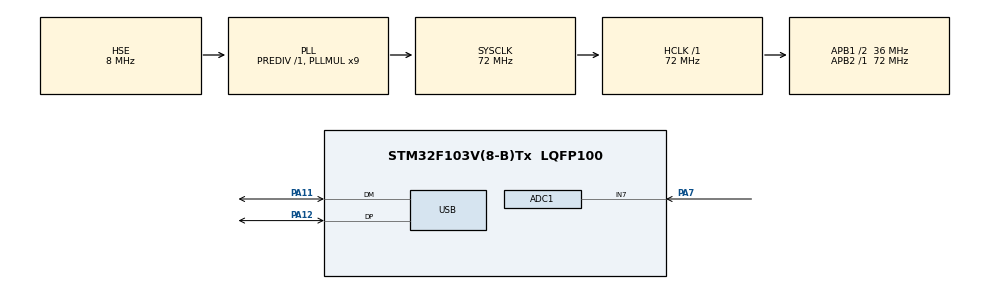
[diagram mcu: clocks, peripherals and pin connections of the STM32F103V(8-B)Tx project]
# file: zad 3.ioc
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ADC1.Channel-0\#ChannelRegularConversion=ADC_CHANNEL_7
ADC1.ContinuousConvMode=ENABLE
ADC1.NbrOfConversion=1
ADC1.NbrOfConversionFlag=1
ADC1.Rank-0\#ChannelRegularConversion=1
ADC1.SamplingTime-0\#ChannelRegularConversion=ADC_SAMPLETIME_1CYCLE_5
ADC1.master=1
Dma.ADC1.0.Direction=DMA_PERIPH_TO_MEMORY
Dma.ADC1.0.Instance=DMA1_Channel1
Dma.ADC1.0.MemDataAlignment=DMA_MDATAALIGN_HALFWORD
Dma.ADC1.0.MemInc=DMA_MINC_DISABLE
Dma.ADC1.0.Mode=DMA_CIRCULAR
Dma.ADC1.0.PeriphDataAlignment=DMA_PDATAALIGN_HALFWORD
Dma.ADC1.0.PeriphInc=DMA_PINC_DISABLE
Dma.ADC1.0.Priority=DMA_PRIORITY_LOW
Dma.Request0=ADC1
Mcu.Family=STM32F1
Mcu.Name=STM32F103V(8-B)Tx
Mcu.Package=LQFP100
NVIC.DMA1_Channel1_IRQn=true\:0\:0\:false\:false\:true\:false\:true\:true
NVIC.PriorityGroup=NVIC_PRIORITYGROUP_4
NVIC.USB_LP_CAN1_RX0_IRQn=true\:0\:0\:false\:false\:true\:false\:true\:true
OSC_IN.Mode=HSE-External-Oscillator
OSC_IN.Signal=RCC_OSC_IN
OSC_OUT.Mode=HSE-External-Oscillator
OSC_OUT.Signal=RCC_OSC_OUT
PA11.Mode=Device
PA11.Signal=USB_DM
PA12.Mode=Device
PA12.Signal=USB_DP
PA13.Mode=JTAG_5_pins
PA13.Signal=SYS_JTMS-SWDIO
PA14.Mode=JTAG_5_pins
PA14.Signal=SYS_JTCK-SWCLK
PA15.Mode=JTAG_5_pins
PA15.Signal=SYS_JTDI
PA7.Signal=ADCx_IN7
PB3.Mode=JTAG_5_pins
PB3.Signal=SYS_JTDO-TRACESWO
PB4.Mode=JTAG_5_pins
PB4.Signal=SYS_NJTRST
PC14-OSC32_IN.Mode=LSE-External-Oscillator
PC14-OSC32_IN.Signal=RCC_OSC32_IN
PC15-OSC32_OUT.Mode=LSE-External-Oscillator
PC15-OSC32_OUT.Signal=RCC_OSC32_OUT
ProjectManager.HeapSize=0x200
ProjectManager.StackSize=0x400
ProjectManager.TargetToolchain=MDK-ARM V5.32
RCC.ADCPresc=RCC_ADCPCLK2_DIV6
RCC.AHBFreq_Value=72000000
RCC.APB1CLKDivider=RCC_HCLK_DIV2
RCC.APB1Freq_Value=36000000
RCC.APB1TimFreq_Value=72000000
RCC.APB2Freq_Value=72000000
RCC.APB2TimFreq_Value=72000000
RCC.HCLKFreq_Value=72000000
RCC.PLLMUL=RCC_PLL_MUL9
RCC.SYSCLKFreq_VALUE=72000000
RCC.SYSCLKSource=RCC_SYSCLKSOURCE_PLLCLK
RCC.USBFreq_Value=48000000
RCC.USBPrescaler=RCC_USBCLKSOURCE_PLL_DIV1_5
SH.ADCx_IN7.0=ADC1_IN7,IN7
USB_DEVICE.CLASS_NAME_FS=CDC
USB_DEVICE.VirtualMode=Cdc
USB_DEVICE.VirtualModeFS=Cdc_FS
VP_USB_DEVICE_VS_USB_DEVICE_CDC_FS.Mode=CDC_FS
board=custom

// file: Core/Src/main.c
/* USER CODE BEGIN Header */
/**
  ******************************************************************************
  * @file           : main.c
  * @brief          : Main program body
  ******************************************************************************
  * @attention
  *
  * Copyright (c) 2023 STMicroelectronics.
  * All rights reserved.
  *
  * This software is licensed under terms that can be found in the LICENSE file
  * in the root directory of this software component.
  * If no LICENSE file comes with this software, it is provided AS-IS.
  *
  ******************************************************************************
  */
/* USER CODE END Header */
#include "main.h"
#include "usb_device.h"

/* USER CODE BEGIN Includes */
#include "USBD_CDC_IF.h"
#include "stdio.h"
#include "lcd4bit.h"
/* USER CODE END Includes */

/* USER CODE BEGIN PD */
#ifdef __GNUC__
#define PUTCHAR_PROTOTYPE int __io_putchar(int ch)
#else
#define PUTCHAR_PROTOTYPE int fputc(int ch, FILE *f)
#endif
PUTCHAR_PROTOTYPE
{
  CDC_Transmit_FS((uint8_t*)&ch,1);
  return ch;
}
/* USER CODE END PD */

ADC_HandleTypeDef hadc1;
DMA_HandleTypeDef hdma_adc1;

/* USER CODE BEGIN PV */
volatile uint32_t ADCVal;
float odleglosc;
char text[10];
Lcd_PortType ports[] = {GPIOC, GPIOC, GPIOC, GPIOC};
Lcd_PinType pins[] = {GPIO_PIN_3, GPIO_PIN_2, GPIO_PIN_1, GPIO_PIN_0};
Lcd_HandleTypeDef lcd;
/* USER CODE END PV */

void SystemClock_Config(void);
static void MX_GPIO_Init(void);
static void MX_DMA_Init(void);
static void MX_ADC1_Init(void);

int main(void)
{

  /* MCU Configuration--------------------------------------------------------*/

  /* Reset of all peripherals, Initializes the Flash interface and the Systick. */
  HAL_Init();

  /* Configure the system clock */
  SystemClock_Config();

  /* Initialize all configured peripherals */
  MX_GPIO_Init();
  MX_DMA_Init();
  MX_ADC1_Init();
  MX_USB_DEVICE_Init();
  /* USER CODE BEGIN 2 */
  HAL_ADC_Start_DMA(&hadc1,&ADCVal,1);
	lcd = Lcd_create(ports, pins, GPIOC, GPIO_PIN_12, GPIOC, GPIO_PIN_10, LCD_4_BIT_MODE);
  /* USER CODE END 2 */

  /* Infinite loop */
  /* USER CODE BEGIN WHILE */
  while (1)
  {
		odleglosc=(3300*ADCVal/4095)/3.2;
		printf("Odleglosc: %f2.3:\n",odleglosc);
		sprintf(text, "%2.3f", odleglosc);
		Lcd_cursor(&lcd,0,0);
		Lcd_string(&lcd,"Odleglosc [cm]:");
		Lcd_cursor(&lcd,1,0);
		Lcd_string(&lcd,text);
		HAL_Delay(1000);
    /* USER CODE END WHILE */

  }
}

void SystemClock_Config(void)
{
  RCC_OscInitTypeDef RCC_OscInitStruct = {0};
  RCC_ClkInitTypeDef RCC_ClkInitStruct = {0};
  RCC_PeriphCLKInitTypeDef PeriphClkInit = {0};

  /** Initializes the RCC Oscillators according to the specified parameters
  * in the RCC_OscInitTypeDef structure.
  */
  RCC_OscInitStruct.OscillatorType = RCC_OSCILLATORTYPE_HSE;
  RCC_OscInitStruct.HSEState = RCC_HSE_ON;
  RCC_OscInitStruct.HSEPredivValue = RCC_HSE_PREDIV_DIV1;
  RCC_OscInitStruct.HSIState = RCC_HSI_ON;
  RCC_OscInitStruct.PLL.PLLState = RCC_PLL_ON;
  RCC_OscInitStruct.PLL.PLLSource = RCC_PLLSOURCE_HSE;
  RCC_OscInitStruct.PLL.PLLMUL = RCC_PLL_MUL9;
  if (HAL_RCC_OscConfig(&RCC_OscInitStruct) != HAL_OK)
  {
    Error_Handler();
  }

  /** Initializes the CPU, AHB and APB buses clocks
  */
  RCC_ClkInitStruct.ClockType = RCC_CLOCKTYPE_HCLK|RCC_CLOCKTYPE_SYSCLK
                              |RCC_CLOCKTYPE_PCLK1|RCC_CLOCKTYPE_PCLK2;
  RCC_ClkInitStruct.SYSCLKSource = RCC_SYSCLKSOURCE_PLLCLK;
  RCC_ClkInitStruct.AHBCLKDivider = RCC_SYSCLK_DIV1;
  RCC_ClkInitStruct.APB1CLKDivider = RCC_HCLK_DIV2;
  RCC_ClkInitStruct.APB2CLKDivider = RCC_HCLK_DIV1;

  if (HAL_RCC_ClockConfig(&RCC_ClkInitStruct, FLASH_LATENCY_2) != HAL_OK)
  {
    Error_Handler();
  }
  PeriphClkInit.PeriphClockSelection = RCC_PERIPHCLK_ADC|RCC_PERIPHCLK_USB;
  PeriphClkInit.AdcClockSelection = RCC_ADCPCLK2_DIV6;
  PeriphClkInit.UsbClockSelection = RCC_USBCLKSOURCE_PLL_DIV1_5;
  if (HAL_RCCEx_PeriphCLKConfig(&PeriphClkInit) != HAL_OK)
  {
    Error_Handler();
  }
}

static void MX_ADC1_Init(void)
{

  ADC_ChannelConfTypeDef sConfig = {0};

  /** Common config
  */
  hadc1.Instance = ADC1;
  hadc1.Init.ScanConvMode = ADC_SCAN_DISABLE;
  hadc1.Init.ContinuousConvMode = ENABLE;
  hadc1.Init.DiscontinuousConvMode = DISABLE;
  hadc1.Init.ExternalTrigConv = ADC_SOFTWARE_START;
  hadc1.Init.DataAlign = ADC_DATAALIGN_RIGHT;
  hadc1.Init.NbrOfConversion = 1;
  if (HAL_ADC_Init(&hadc1) != HAL_OK)
  {
    Error_Handler();
  }

  /** Configure Regular Channel
  */
  sConfig.Channel = ADC_CHANNEL_7;
  sConfig.Rank = ADC_REGULAR_RANK_1;
  sConfig.SamplingTime = ADC_SAMPLETIME_1CYCLE_5;
  if (HAL_ADC_ConfigChannel(&hadc1, &sConfig) != HAL_OK)
  {
    Error_Handler();
  }

}

static void MX_DMA_Init(void)
{

  /* DMA controller clock enable */
  __HAL_RCC_DMA1_CLK_ENABLE();

  /* DMA interrupt init */
  /* DMA1_Channel1_IRQn interrupt configuration */
  HAL_NVIC_SetPriority(DMA1_Channel1_IRQn, 0, 0);
  HAL_NVIC_EnableIRQ(DMA1_Channel1_IRQn);

}

static void MX_GPIO_Init(void)
{

  /* GPIO Ports Clock Enable */
  __HAL_RCC_GPIOC_CLK_ENABLE();
  __HAL_RCC_GPIOA_CLK_ENABLE();
  __HAL_RCC_GPIOB_CLK_ENABLE();

}

void Error_Handler(void)
{
  __disable_irq();
  while (1)
  {
  }
}
